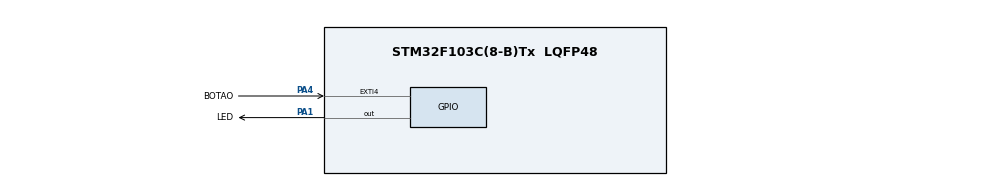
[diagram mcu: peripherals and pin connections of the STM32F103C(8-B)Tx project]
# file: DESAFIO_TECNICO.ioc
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Mcu.Family=STM32F1
Mcu.Name=STM32F103C(8-B)Tx
Mcu.Package=LQFP48
NVIC.EXTI4_IRQn=true\:0\:0\:false\:false\:true\:true\:true\:true
NVIC.PriorityGroup=NVIC_PRIORITYGROUP_4
PA1.GPIO_Label=LED
PA1.Signal=GPIO_Output
PA4.GPIO_Label=BOTAO
PA4.GPIO_ModeDefaultEXTI=GPIO_MODE_IT_FALLING
PA4.GPIO_PuPd=GPIO_PULLUP
PA4.Signal=GPXTI4
PD0-OSC_IN.Mode=HSE-External-Oscillator
PD0-OSC_IN.Signal=RCC_OSC_IN
PD1-OSC_OUT.Mode=HSE-External-Oscillator
PD1-OSC_OUT.Signal=RCC_OSC_OUT
ProjectManager.HeapSize=0x200
ProjectManager.StackSize=0x400
ProjectManager.TargetToolchain=STM32CubeIDE
RCC.APB1Freq_Value=8000000
RCC.APB2Freq_Value=8000000
RCC.SYSCLKSource=RCC_SYSCLKSOURCE_HSE
board=custom

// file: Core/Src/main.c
/* USER CODE BEGIN Header */
/**
 ******************************************************************************
 * @file           : main.c
 * @brief          : Main program body
 ******************************************************************************
 * @attention
 *
 * Copyright (c) 2023 STMicroelectronics.
 * All rights reserved.
 *
 * This software is licensed under terms that can be found in the LICENSE file
 * in the root directory of this software component.
 * If no LICENSE file comes with this software, it is provided AS-IS.
 *
 ******************************************************************************
 */
/* USER CODE END Header */
#include "main.h"

void SystemClock_Config(void);
static void MX_GPIO_Init(void);

/* USER CODE BEGIN 0 */
uint8_t pressionado = 0; // variável utilizada para detectar se a interrupção aconteceu

/* USER CODE END 0 */

int main(void) {
	/* USER CODE BEGIN 1 */
	uint32_t tempo[3] = { 500, 250, 1000 }; //Declara o vetor com os delays desejados em ms
	uint8_t cursor = 0; // Declara uma variável para excursionar pelo vetor de tempo
	uint32_t last_pressed = 0; // variavel para pegar o momento em que o botao foi pressionado pela última vez
	uint8_t debounce_ok = 0; // variavel que define se a detecção do botão pressionado será levada em conta

	/* USER CODE END 1 */

	/* MCU Configuration--------------------------------------------------------*/

	/* Reset of all peripherals, Initializes the Flash interface and the Systick. */
	HAL_Init();

	/* Configure the system clock */
	SystemClock_Config();

	/* Initialize all configured peripherals */
	MX_GPIO_Init();

	/* Infinite loop */
	while (1) {

		/* USER CODE BEGIN 3 */
		if (last_pressed < HAL_GetTick() + 500)
			debounce_ok = 1; // espera meio segundo antes de permitir que o botao seja detectado novamente

		if (pressionado == 1 && debounce_ok) {// quando detecta que o botão foi pressionado verifica se tempo de debounce já passou
			last_pressed = HAL_GetTick(); // Pega o momento em ms em que o botão foi pressionado por último
			if (cursor < 2)
				cursor++; // incrementa a variável cursor para alterar a frequência em que o led pisca
			else
				cursor = 0; // garante que o cursor fique entre os valores do vetor;
			debounce_ok = 0; // zera a variável de debounce
			pressionado = 0;
		}

		HAL_GPIO_WritePin(GPIOA, LED_Pin, 1); // Altera o estado do LED

		HAL_Delay(tempo[cursor]); // Aguarda pelo tempo definido pelo cursor

		HAL_GPIO_WritePin(GPIOA, LED_Pin, 0); // Altera o estado do LED

		HAL_Delay(tempo[cursor]); // Aguarda pelo tempo definido pelo cursor
	}
	/* USER CODE END 3 */
}

void SystemClock_Config(void) {
	RCC_OscInitTypeDef RCC_OscInitStruct = { 0 };
	RCC_ClkInitTypeDef RCC_ClkInitStruct = { 0 };

	/** Initializes the RCC Oscillators according to the specified parameters
	 * in the RCC_OscInitTypeDef structure.
	 */
	RCC_OscInitStruct.OscillatorType = RCC_OSCILLATORTYPE_HSE;
	RCC_OscInitStruct.HSEState = RCC_HSE_ON;
	RCC_OscInitStruct.PLL.PLLState = RCC_PLL_NONE;
	if (HAL_RCC_OscConfig(&RCC_OscInitStruct) != HAL_OK) {
		Error_Handler();
	}

	/** Initializes the CPU, AHB and APB buses clocks
	 */
	RCC_ClkInitStruct.ClockType = RCC_CLOCKTYPE_HCLK | RCC_CLOCKTYPE_SYSCLK
			| RCC_CLOCKTYPE_PCLK1 | RCC_CLOCKTYPE_PCLK2;
	RCC_ClkInitStruct.SYSCLKSource = RCC_SYSCLKSOURCE_HSE;
	RCC_ClkInitStruct.AHBCLKDivider = RCC_SYSCLK_DIV1;
	RCC_ClkInitStruct.APB1CLKDivider = RCC_HCLK_DIV1;
	RCC_ClkInitStruct.APB2CLKDivider = RCC_HCLK_DIV1;

	if (HAL_RCC_ClockConfig(&RCC_ClkInitStruct, FLASH_LATENCY_0) != HAL_OK) {
		Error_Handler();
	}
}

static void MX_GPIO_Init(void) {
	GPIO_InitTypeDef GPIO_InitStruct = { 0 };

	/* GPIO Ports Clock Enable */
	__HAL_RCC_GPIOD_CLK_ENABLE();
	__HAL_RCC_GPIOA_CLK_ENABLE();

	/*Configure GPIO pin Output Level */
	HAL_GPIO_WritePin(LED_GPIO_Port, LED_Pin, GPIO_PIN_RESET);

	/*Configure GPIO pin : LED_Pin */
	GPIO_InitStruct.Pin = LED_Pin;
	GPIO_InitStruct.Mode = GPIO_MODE_OUTPUT_PP;
	GPIO_InitStruct.Pull = GPIO_NOPULL;
	GPIO_InitStruct.Speed = GPIO_SPEED_FREQ_LOW;
	HAL_GPIO_Init(LED_GPIO_Port, &GPIO_InitStruct);

	/*Configure GPIO pin : BOTAO_Pin */
	GPIO_InitStruct.Pin = BOTAO_Pin;
	GPIO_InitStruct.Mode = GPIO_MODE_IT_FALLING;
	GPIO_InitStruct.Pull = GPIO_PULLUP;
	HAL_GPIO_Init(BOTAO_GPIO_Port, &GPIO_InitStruct);

	/* EXTI interrupt init*/
	HAL_NVIC_SetPriority(EXTI4_IRQn, 0, 0);
	HAL_NVIC_EnableIRQ(EXTI4_IRQn);

}

void Error_Handler(void) {
	__disable_irq();
	while (1) {
	}
}

void HAL_GPIO_EXTI_Callback(uint16_t GPIO_Pin) {
	if (GPIO_Pin == GPIO_PIN_4) // Caso a interrupção aconteça no pino 4
	{
		pressionado = 1; // detecta que a interrupção aconteceu
	}
}
